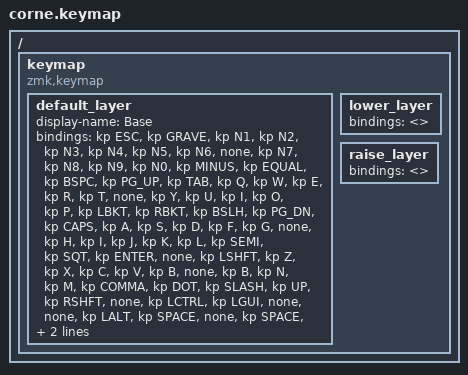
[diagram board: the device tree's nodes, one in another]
/*
 * Copyright (c) 2020 The ZMK Contributors
 *
 * SPDX-License-Identifier: MIT
 */

#include <behaviors.dtsi>
#include <dt-bindings/zmk/keys.h>
#include <dt-bindings/zmk/bt.h>

/ {
        keymap {
                compatible = "zmk,keymap";

                default_layer {
// -----------------------------------------------------------------------------------------
// |  ECS |  ~  |  1  |  2  |  3  |  4  |  5  |  6  |        7  |  8  |  9  |  0  |  -  |  +  | BSPC | 
// | PG_UP| TAB |  Q  |  W  |  E  |  R  |  T  |     |  Y  |  U  |  I  |  O  |  P  |  [  |  ]  |   \  |
// | PG_DW| CAP |  A  |  S  |  D  |  F  |  G  |     |  H  |  I  |  J  |  K  |  L  |  ;  |  '  | ENTR |
// |      | SHFT|  Z  |  X  |  C  |  V  |  B  |     |  B  |  N  |  M  |  ,  |  .  |  /  |  UP | SHFT | 
//        | CTRL| WIN |     |     | ALT |SPACE|     |SPACE|  FN |     |     |     | LEFT| DOWN|RIGHT |      
                        display-name = "Base";
                        bindings = <
   &kp ESC   &kp GRAVE  &kp N1          &kp N2  &kp N3  &kp N4   &kp N5         &kp N6  &none           &kp N7  &kp N8  &kp N9          &kp N0  &kp MINUS       &kp EQUAL       &kp BSPC 
   &kp PG_UP &kp TAB    &kp Q           &kp W   &kp E   &kp R    &kp T          &none   &kp Y           &kp U   &kp I   &kp O           &kp P   &kp LBKT        &kp RBKT        &kp BSLH
   &kp PG_DN &kp CAPS   &kp A           &kp S   &kp D   &kp F    &kp G          &none   &kp H           &kp I   &kp J   &kp K           &kp L   &kp SEMI        &kp SQT         &kp ENTER
   &none     &kp LSHFT  &kp Z           &kp X   &kp C   &kp V    &kp B          &none   &kp B           &kp N   &kp M   &kp COMMA       &kp DOT &kp SLASH       &kp UP          &kp RSHFT
   &none     &kp LCTRL  &kp LGUI        &none   &none   &kp LALT &kp SPACE      &none   &kp SPACE       &mo 1   &none   &none           &none   &kp LEFT        &kp DOWN        &kp RIGHT
                        >;
                };
                lower_layer {
                        bindings = <>; 
                };

                raise_layer {
                        bindings = <>; 
                };
        };
};
